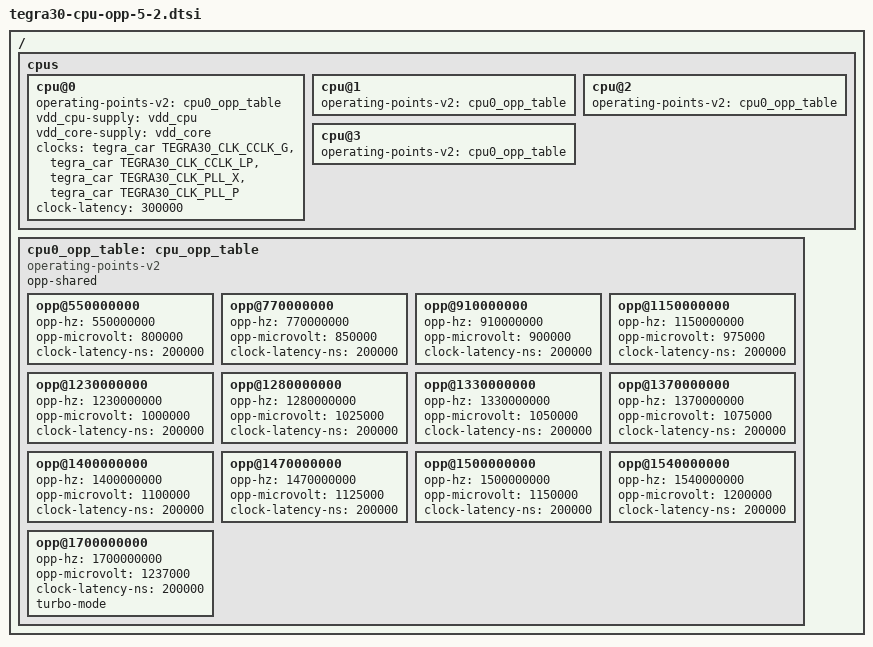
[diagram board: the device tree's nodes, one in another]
/* DVFS tables for Tegra3 CPU-speedo 5, CPU-process 2 */

#include <dt-bindings/clock/tegra30-car.h>

/ {
	cpus {
		cpu@0 {
			operating-points-v2 = <&cpu0_opp_table>;
			vdd_cpu-supply = <&vdd_cpu>;
			vdd_core-supply = <&vdd_core>;
			clocks = <&tegra_car TEGRA30_CLK_CCLK_G>,
				 <&tegra_car TEGRA30_CLK_CCLK_LP>,
				 <&tegra_car TEGRA30_CLK_PLL_X>,
				 <&tegra_car TEGRA30_CLK_PLL_P>;
			clock-names = "cpu_g", "cpu_lp", "pll_x", "pll_p";
			/* FIXME: what's the real transition time? */
			clock-latency = <300000>;
		};
		cpu@1 {
			operating-points-v2 = <&cpu0_opp_table>;
		};
		cpu@2 {
			operating-points-v2 = <&cpu0_opp_table>;
		};
		cpu@3 {
			operating-points-v2 = <&cpu0_opp_table>;
		};
	};

	cpu0_opp_table: cpu_opp_table {
		compatible = "operating-points-v2";
		opp-shared;

		opp@550000000 {
			opp-hz = /bits/ 64 <550000000>;
			opp-microvolt = <800000>;
			clock-latency-ns = <200000>;
		};
		opp@770000000 {
			opp-hz = /bits/ 64 <770000000>;
			opp-microvolt = <850000>;
			clock-latency-ns = <200000>;
		};
		opp@910000000 {
			opp-hz = /bits/ 64 <910000000>;
			opp-microvolt = <900000>;
			clock-latency-ns = <200000>;
		};
		opp@1150000000 {
			opp-hz = /bits/ 64 <1150000000>;
			opp-microvolt = <975000>;
			clock-latency-ns = <200000>;
		};
		opp@1230000000 {
			opp-hz = /bits/ 64 <1230000000>;
			opp-microvolt = <1000000>;
			clock-latency-ns = <200000>;
		};
		opp@1280000000 {
			opp-hz = /bits/ 64 <1280000000>;
			opp-microvolt = <1025000>;
			clock-latency-ns = <200000>;
		};
		opp@1330000000 {
			opp-hz = /bits/ 64 <1330000000>;
			opp-microvolt = <1050000>;
			clock-latency-ns = <200000>;
		};
		opp@1370000000 {
			opp-hz = /bits/ 64 <1370000000>;
			opp-microvolt = <1075000>;
			clock-latency-ns = <200000>;
		};
		opp@1400000000 {
			opp-hz = /bits/ 64 <1400000000>;
			opp-microvolt = <1100000>;
			clock-latency-ns = <200000>;
		};
		opp@1470000000 {
			opp-hz = /bits/ 64 <1470000000>;
			opp-microvolt = <1125000>;
			clock-latency-ns = <200000>;
		};
		opp@1500000000 {
			opp-hz = /bits/ 64 <1500000000>;
			opp-microvolt = <1150000>;
			clock-latency-ns = <200000>;
		};
		opp@1540000000 {
			opp-hz = /bits/ 64 <1540000000>;
			opp-microvolt = <1200000>;
			clock-latency-ns = <200000>;
		};
		opp@1700000000 {
			opp-hz = /bits/ 64 <1700000000>;
			opp-microvolt = <1237000>;
			clock-latency-ns = <200000>;
			turbo-mode;
		};
	};
};
